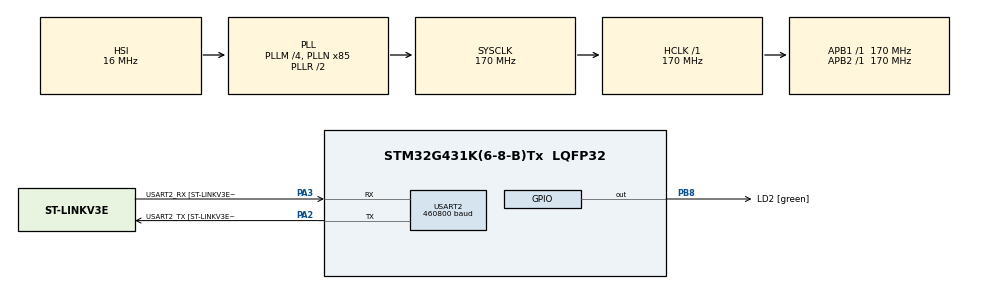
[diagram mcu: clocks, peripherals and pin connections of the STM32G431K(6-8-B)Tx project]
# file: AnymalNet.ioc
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Mcu.Family=STM32G4
Mcu.Name=STM32G431K(6-8-B)Tx
Mcu.Package=LQFP32
NVIC.PriorityGroup=NVIC_PRIORITYGROUP_4
NVIC.USART2_IRQn=true\:0\:0\:false\:false\:true\:true\:true\:true
PA13.GPIO_Label=T_SWDIO
PA13.Mode=Serial_Wire
PA13.Signal=SYS_JTMS-SWDIO
PA14.GPIO_Label=T_SWCLK
PA14.Mode=Serial_Wire
PA14.Signal=SYS_JTCK-SWCLK
PA2.GPIO_Label=USART2_TX [ST-LINKV3E_VCP_RX]
PA2.Mode=Asynchronous
PA2.Signal=USART2_TX
PA3.GPIO_Label=USART2_RX [ST-LINKV3E_VCP_TX]
PA3.Mode=Asynchronous
PA3.Signal=USART2_RX
PB3.GPIO_Label=T_SWO
PB3.Signal=SYS_JTDO-SWO
PB8-BOOT0.GPIO_Label=LD2 [green]
PB8-BOOT0.Signal=GPIO_Output
ProjectManager.HeapSize=0x800
ProjectManager.StackSize=0x800
ProjectManager.TargetToolchain=STM32CubeIDE
RCC.ADC12Freq_Value=170000000
RCC.AHBFreq_Value=170000000
RCC.APB1Freq_Value=170000000
RCC.APB1TimFreq_Value=170000000
RCC.APB2Freq_Value=170000000
RCC.APB2TimFreq_Value=170000000
RCC.CortexFreq_Value=170000000
RCC.EXTERNAL_CLOCK_VALUE=12288000
RCC.HCLKFreq_Value=170000000
RCC.HSE_VALUE=8000000
RCC.HSI48_VALUE=48000000
RCC.HSI_VALUE=16000000
RCC.LSE_VALUE=32768
RCC.PLLM=RCC_PLLM_DIV4
RCC.PLLN=85
RCC.SYSCLKFreq_VALUE=170000000
RCC.SYSCLKSource=RCC_SYSCLKSOURCE_PLLCLK
RCC.USBFreq_Value=170000000
RCC.VCOOutputFreq_Value=340000000
STMicroelectronics.X-CUBE-AI.8.1.0.ActivationBufferSizeList=1536
STMicroelectronics.X-CUBE-AI.8.1.0.ActivationBuffers=pool0
STMicroelectronics.X-CUBE-AI.8.1.0.ActivationNames=pool0
STMicroelectronics.X-CUBE-AI.8.1.0.ActivationSizes=AI_NETWORK_DATA_ACTIVATION_1_SIZE
STMicroelectronics.X-CUBE-AI.8.1.0.ApplicationCcDeviceJjApplication=ApplicationTemplate
STMicroelectronics.X-CUBE-AI.8.1.0.HeapSize=0x800
STMicroelectronics.X-CUBE-AI.8.1.0.InternalRamActivationBufferMaxSize=AI_NETWORK_DATA_ACTIVATIONS_SIZE
STMicroelectronics.X-CUBE-AI.8.1.0.LatestDirectoryUsed-cf5ea41ab4293220509bf5922da8b113a5860cfb809b5faa2e4b3f142f904e63=/home/tyler/MachineLearning/git/GuardDog/isaac/IsaacGymEnvs/isaacgymenvs
STMicroelectronics.X-CUBE-AI.8.1.0.MaximumNumberOfInputLayer=1
STMicroelectronics.X-CUBE-AI.8.1.0.MaximumNumberOfOutputLayer=3
STMicroelectronics.X-CUBE-AI.8.1.0.MaximumSizeOfInputLayer=1
STMicroelectronics.X-CUBE-AI.8.1.0.MaximumSizeOfOutputLayer=1,1,1
STMicroelectronics.X-CUBE-AI.8.1.0.ModelActualCompression-cf5ea41ab4293220509bf5922da8b113a5860cfb809b5faa2e4b3f142f904e63=3.73
STMicroelectronics.X-CUBE-AI.8.1.0.ModelCompression-cf5ea41ab4293220509bf5922da8b113a5860cfb809b5faa2e4b3f142f904e63=Low
STMicroelectronics.X-CUBE-AI.8.1.0.ModelFlashOccupation-cf5ea41ab4293220509bf5922da8b113a5860cfb809b5faa2e4b3f142f904e63=92696
STMicroelectronics.X-CUBE-AI.8.1.0.ModelHashList=cf5ea41ab4293220509bf5922da8b113a5860cfb809b5faa2e4b3f142f904e63
STMicroelectronics.X-CUBE-AI.8.1.0.ModelKind-cf5ea41ab4293220509bf5922da8b113a5860cfb809b5faa2e4b3f142f904e63=ONNX
STMicroelectronics.X-CUBE-AI.8.1.0.ModelMacc-cf5ea41ab4293220509bf5922da8b113a5860cfb809b5faa2e4b3f142f904e63=59889
STMicroelectronics.X-CUBE-AI.8.1.0.ModelName-cf5ea41ab4293220509bf5922da8b113a5860cfb809b5faa2e4b3f142f904e63=network
STMicroelectronics.X-CUBE-AI.8.1.0.ModelNameList=network
STMicroelectronics.X-CUBE-AI.8.1.0.ModelRamOccupation-cf5ea41ab4293220509bf5922da8b113a5860cfb809b5faa2e4b3f142f904e63=1536
STMicroelectronics.X-CUBE-AI.8.1.0.ModelStructureFile-cf5ea41ab4293220509bf5922da8b113a5860cfb809b5faa2e4b3f142f904e63=/home/tyler/MachineLearning/git/GuardDog/isaac/IsaacGymEnvs/isaacgymenvs/anymal.onnx
STMicroelectronics.X-CUBE-AI.8.1.0.ModelType-cf5ea41ab4293220509bf5922da8b113a5860cfb809b5faa2e4b3f142f904e63=Saved model
STMicroelectronics.X-CUBE-AI.8.1.0.ReadyForCodeGeneration=true
STMicroelectronics.X-CUBE-AI.8.1.0.StackSize=0x800
STMicroelectronics.X-CUBE-AI.8.1.0.WorkingBufferStartAddrList=0xFFFFFFFF
STMicroelectronics.X-CUBE-AI.8.1.0.XAaCUBEAaAICcArtificialOoIntelligenceJjCore=true
STMicroelectronics.X-CUBE-AI.8.1.0.copyWeightToRam=false
STMicroelectronics.X-CUBE-AI.8.1.0.copyWeightToRam-cf5ea41ab4293220509bf5922da8b113a5860cfb809b5faa2e4b3f142f904e63=false
STMicroelectronics.X-CUBE-AI.8.1.0.customLayerConfigEnabled=false
STMicroelectronics.X-CUBE-AI.8.1.0.customLayerConfigEnabled-cf5ea41ab4293220509bf5922da8b113a5860cfb809b5faa2e4b3f142f904e63=false
STMicroelectronics.X-CUBE-AI.8.1.0.noOnnxIoTranspose=false
STMicroelectronics.X-CUBE-AI.8.1.0.noOnnxIoTranspose-cf5ea41ab4293220509bf5922da8b113a5860cfb809b5faa2e4b3f142f904e63=false
STMicroelectronics.X-CUBE-AI.8.1.0.useInputAllocation=true
STMicroelectronics.X-CUBE-AI.8.1.0.useInputAllocation-cf5ea41ab4293220509bf5922da8b113a5860cfb809b5faa2e4b3f142f904e63=true
STMicroelectronics.X-CUBE-AI.8.1.0.useOutputAllocation=true
STMicroelectronics.X-CUBE-AI.8.1.0.useOutputAllocation-cf5ea41ab4293220509bf5922da8b113a5860cfb809b5faa2e4b3f142f904e63=true
TIM2.Prescaler=170
USART2.BaudRate=460800
USART2.VirtualMode-Asynchronous=VM_ASYNC
USART2.WordLength=WORDLENGTH_8B
VP_CRC_VS_CRC.Mode=CRC_Activate
VP_STMicroelectronics.X-CUBE-AI_VS_ArtificialOoIntelligenceJjXAaCUBEAaAI_8.1.0.Mode=ArtificialOoIntelligenceJjXAaCUBEAaAI
VP_STMicroelectronics.X-CUBE-AI_VS_DeviceJjApplication_8.1.0.Mode=DeviceJjApplication
VP_SYS_VS_DBSignals.Mode=DisableDeadBatterySignals
VP_TIM2_VS_ClockSourceINT.Mode=Internal
board=NUCLEO-G431KB

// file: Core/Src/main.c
/* USER CODE BEGIN Header */
/**
  ******************************************************************************
  * @file           : main.c
  * @brief          : Main program body
  ******************************************************************************
  * @attention
  *
  * Copyright (c) 2024 STMicroelectronics.
  * All rights reserved.
  *
  * This software is licensed under terms that can be found in the LICENSE file
  * in the root directory of this software component.
  * If no LICENSE file comes with this software, it is provided AS-IS.
  *
  ******************************************************************************
  */
/* USER CODE END Header */
#include "main.h"
#include "app_x-cube-ai.h"

/* USER CODE BEGIN Includes */
#include <stdint.h>
#include "network.h"
/* USER CODE END Includes */

CRC_HandleTypeDef hcrc;

TIM_HandleTypeDef htim2;

UART_HandleTypeDef huart2;

/* USER CODE BEGIN PV */
union obsUnion {
    float floatValue[48];
    uint8_t bytes[48 * sizeof(float)];
};
union obsUnion obs_data;

union actUnion {
    float floatValue[12];
    uint8_t bytes[12 * sizeof(float)];
};
union actUnion act_data;

ai_float in_data1[AI_NETWORK_IN_1_SIZE];
ai_float out_data1[AI_NETWORK_OUT_1_SIZE];
ai_float out_data2[AI_NETWORK_OUT_2_SIZE];
ai_float out_data3[AI_NETWORK_OUT_3_SIZE];
uint8_t data_flag;
/* USER CODE END PV */

void SystemClock_Config(void);
static void MX_GPIO_Init(void);
static void MX_USART2_UART_Init(void);
static void MX_CRC_Init(void);
static void MX_TIM2_Init(void);

int main(void)
{
  /* USER CODE BEGIN 1 */
  data_flag=0;
  /* USER CODE END 1 */

  /* MCU Configuration--------------------------------------------------------*/

  /* Reset of all peripherals, Initializes the Flash interface and the Systick. */
  HAL_Init();

  /* Configure the system clock */
  SystemClock_Config();

  /* Initialize all configured peripherals */
  MX_GPIO_Init();
  MX_USART2_UART_Init();
  MX_CRC_Init();
  MX_TIM2_Init();
  MX_X_CUBE_AI_Init();
  /* USER CODE BEGIN 2 */
  HAL_UART_Receive_IT(&huart2, obs_data.bytes, sizeof(obs_data.bytes));
  /* USER CODE END 2 */

  /* Infinite loop */
  /* USER CODE BEGIN WHILE */
  while (1)
  {
	if(data_flag)
	{

	  TIM2->CNT = 0;
	  HAL_TIM_Base_Start(&htim2);
	  for(int i=0; i<48; i++)
	  {
		  in_data1[i] = obs_data.floatValue[i];
	  }
	  MX_X_CUBE_AI_Process();
	  HAL_TIM_Base_Stop(&htim2);
	  for(int i=0; i<12; i++)
	  {
		  act_data.floatValue[i] = out_data1[i];
	  }
	  data_flag = 0;
	  HAL_UART_Transmit(&huart2, act_data.bytes, sizeof(act_data.bytes), 100);
	  HAL_UART_Receive_IT(&huart2, obs_data.bytes, sizeof(obs_data.bytes));
	}
    /* USER CODE END WHILE */

  MX_X_CUBE_AI_Process();
  }
}

void SystemClock_Config(void)
{
  RCC_OscInitTypeDef RCC_OscInitStruct = {0};
  RCC_ClkInitTypeDef RCC_ClkInitStruct = {0};

  /** Configure the main internal regulator output voltage
  */
  HAL_PWREx_ControlVoltageScaling(PWR_REGULATOR_VOLTAGE_SCALE1_BOOST);

  /** Initializes the RCC Oscillators according to the specified parameters
  * in the RCC_OscInitTypeDef structure.
  */
  RCC_OscInitStruct.OscillatorType = RCC_OSCILLATORTYPE_HSI;
  RCC_OscInitStruct.HSIState = RCC_HSI_ON;
  RCC_OscInitStruct.HSICalibrationValue = RCC_HSICALIBRATION_DEFAULT;
  RCC_OscInitStruct.PLL.PLLState = RCC_PLL_ON;
  RCC_OscInitStruct.PLL.PLLSource = RCC_PLLSOURCE_HSI;
  RCC_OscInitStruct.PLL.PLLM = RCC_PLLM_DIV4;
  RCC_OscInitStruct.PLL.PLLN = 85;
  RCC_OscInitStruct.PLL.PLLP = RCC_PLLP_DIV2;
  RCC_OscInitStruct.PLL.PLLQ = RCC_PLLQ_DIV2;
  RCC_OscInitStruct.PLL.PLLR = RCC_PLLR_DIV2;
  if (HAL_RCC_OscConfig(&RCC_OscInitStruct) != HAL_OK)
  {
    Error_Handler();
  }

  /** Initializes the CPU, AHB and APB buses clocks
  */
  RCC_ClkInitStruct.ClockType = RCC_CLOCKTYPE_HCLK|RCC_CLOCKTYPE_SYSCLK
                              |RCC_CLOCKTYPE_PCLK1|RCC_CLOCKTYPE_PCLK2;
  RCC_ClkInitStruct.SYSCLKSource = RCC_SYSCLKSOURCE_PLLCLK;
  RCC_ClkInitStruct.AHBCLKDivider = RCC_SYSCLK_DIV1;
  RCC_ClkInitStruct.APB1CLKDivider = RCC_HCLK_DIV1;
  RCC_ClkInitStruct.APB2CLKDivider = RCC_HCLK_DIV1;

  if (HAL_RCC_ClockConfig(&RCC_ClkInitStruct, FLASH_LATENCY_4) != HAL_OK)
  {
    Error_Handler();
  }
}

static void MX_CRC_Init(void)
{

  hcrc.Instance = CRC;
  hcrc.Init.DefaultPolynomialUse = DEFAULT_POLYNOMIAL_ENABLE;
  hcrc.Init.DefaultInitValueUse = DEFAULT_INIT_VALUE_ENABLE;
  hcrc.Init.InputDataInversionMode = CRC_INPUTDATA_INVERSION_NONE;
  hcrc.Init.OutputDataInversionMode = CRC_OUTPUTDATA_INVERSION_DISABLE;
  hcrc.InputDataFormat = CRC_INPUTDATA_FORMAT_BYTES;
  if (HAL_CRC_Init(&hcrc) != HAL_OK)
  {
    Error_Handler();
  }

}

static void MX_TIM2_Init(void)
{

  TIM_ClockConfigTypeDef sClockSourceConfig = {0};
  TIM_MasterConfigTypeDef sMasterConfig = {0};

  htim2.Instance = TIM2;
  htim2.Init.Prescaler = 170;
  htim2.Init.CounterMode = TIM_COUNTERMODE_UP;
  htim2.Init.Period = 4.294967295E9;
  htim2.Init.ClockDivision = TIM_CLOCKDIVISION_DIV1;
  htim2.Init.AutoReloadPreload = TIM_AUTORELOAD_PRELOAD_DISABLE;
  if (HAL_TIM_Base_Init(&htim2) != HAL_OK)
  {
    Error_Handler();
  }
  sClockSourceConfig.ClockSource = TIM_CLOCKSOURCE_INTERNAL;
  if (HAL_TIM_ConfigClockSource(&htim2, &sClockSourceConfig) != HAL_OK)
  {
    Error_Handler();
  }
  sMasterConfig.MasterOutputTrigger = TIM_TRGO_RESET;
  sMasterConfig.MasterSlaveMode = TIM_MASTERSLAVEMODE_DISABLE;
  if (HAL_TIMEx_MasterConfigSynchronization(&htim2, &sMasterConfig) != HAL_OK)
  {
    Error_Handler();
  }

}

static void MX_USART2_UART_Init(void)
{

  huart2.Instance = USART2;
  huart2.Init.BaudRate = 460800;
  huart2.Init.WordLength = UART_WORDLENGTH_8B;
  huart2.Init.StopBits = UART_STOPBITS_1;
  huart2.Init.Parity = UART_PARITY_NONE;
  huart2.Init.Mode = UART_MODE_TX_RX;
  huart2.Init.HwFlowCtl = UART_HWCONTROL_NONE;
  huart2.Init.OverSampling = UART_OVERSAMPLING_16;
  huart2.Init.OneBitSampling = UART_ONE_BIT_SAMPLE_DISABLE;
  huart2.Init.ClockPrescaler = UART_PRESCALER_DIV1;
  huart2.AdvancedInit.AdvFeatureInit = UART_ADVFEATURE_NO_INIT;
  if (HAL_UART_Init(&huart2) != HAL_OK)
  {
    Error_Handler();
  }
  if (HAL_UARTEx_SetTxFifoThreshold(&huart2, UART_TXFIFO_THRESHOLD_1_8) != HAL_OK)
  {
    Error_Handler();
  }
  if (HAL_UARTEx_SetRxFifoThreshold(&huart2, UART_RXFIFO_THRESHOLD_1_8) != HAL_OK)
  {
    Error_Handler();
  }
  if (HAL_UARTEx_DisableFifoMode(&huart2) != HAL_OK)
  {
    Error_Handler();
  }

}

static void MX_GPIO_Init(void)
{
  GPIO_InitTypeDef GPIO_InitStruct = {0};

  /* GPIO Ports Clock Enable */
  __HAL_RCC_GPIOA_CLK_ENABLE();
  __HAL_RCC_GPIOB_CLK_ENABLE();

  /*Configure GPIO pin Output Level */
  HAL_GPIO_WritePin(LD2_GPIO_Port, LD2_Pin, GPIO_PIN_RESET);

  /*Configure GPIO pin : LD2_Pin */
  GPIO_InitStruct.Pin = LD2_Pin;
  GPIO_InitStruct.Mode = GPIO_MODE_OUTPUT_PP;
  GPIO_InitStruct.Pull = GPIO_NOPULL;
  GPIO_InitStruct.Speed = GPIO_SPEED_FREQ_LOW;
  HAL_GPIO_Init(LD2_GPIO_Port, &GPIO_InitStruct);

}

/* USER CODE BEGIN 4 */
void HAL_UART_RxCpltCallback(UART_HandleTypeDef *huart)
{
  // We will set a data flag here and execute in the main loop
  data_flag = 1;
}
void HAL_UART_TxCpltCallback(UART_HandleTypeDef *huart)
{

}
/* USER CODE END 4 */

void Error_Handler(void)
{
  __disable_irq();
  while (1)
  {
  }
}
